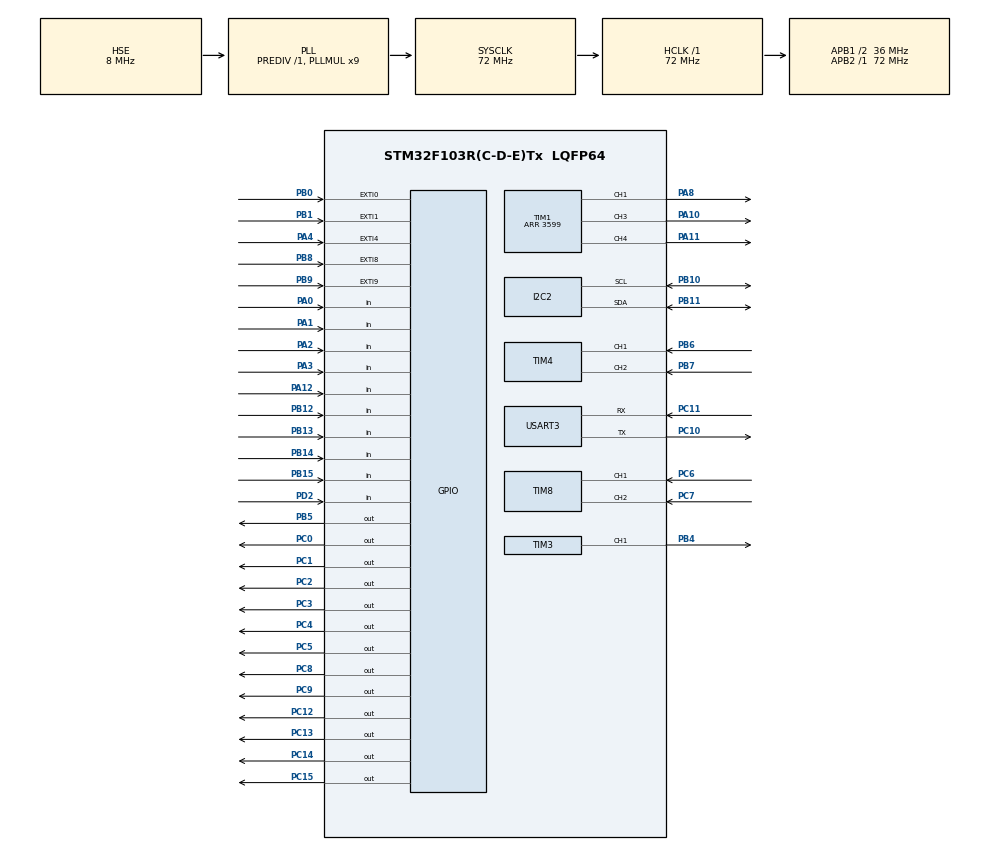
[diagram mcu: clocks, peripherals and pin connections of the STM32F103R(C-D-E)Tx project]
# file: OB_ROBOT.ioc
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Mcu.Family=STM32F1
Mcu.Name=STM32F103R(C-D-E)Tx
Mcu.Package=LQFP64
NVIC.EXTI0_IRQn=true\:0\:0\:false\:false\:true\:true\:true\:true
NVIC.EXTI1_IRQn=true\:0\:0\:false\:false\:true\:true\:true\:true
NVIC.EXTI4_IRQn=true\:0\:0\:false\:false\:true\:true\:true\:true
NVIC.EXTI9_5_IRQn=true\:0\:0\:false\:false\:true\:true\:true\:true
NVIC.PriorityGroup=NVIC_PRIORITYGROUP_4
NVIC.TIM2_IRQn=true\:1\:0\:false\:false\:true\:true\:true\:true
NVIC.USART3_IRQn=true\:0\:0\:false\:false\:true\:true\:true\:true
PA0-WKUP.GPIO_PuPd=GPIO_PULLDOWN
PA0-WKUP.Signal=GPIO_Input
PA1.GPIO_PuPd=GPIO_PULLUP
PA1.Signal=GPIO_Input
PA10.Signal=S_TIM1_CH3
PA11.Signal=S_TIM1_CH4
PA12.GPIO_PuPd=GPIO_PULLUP
PA12.Signal=GPIO_Input
PA13.Mode=Serial_Wire
PA13.Signal=SYS_JTMS-SWDIO
PA14.Mode=Serial_Wire
PA14.Signal=SYS_JTCK-SWCLK
PA2.GPIO_PuPd=GPIO_PULLUP
PA2.Signal=GPIO_Input
PA3.GPIO_PuPd=GPIO_PULLUP
PA3.Signal=GPIO_Input
PA4.GPIO_ModeDefaultEXTI=GPIO_MODE_IT_RISING
PA4.GPIO_PuPd=GPIO_NOPULL
PA4.Signal=GPXTI4
PA8.Signal=S_TIM1_CH1
PB0.GPIO_ModeDefaultEXTI=GPIO_MODE_IT_RISING_FALLING
PB0.GPIO_PuPd=GPIO_PULLUP
PB0.Signal=GPXTI0
PB1.GPIO_ModeDefaultEXTI=GPIO_MODE_IT_RISING_FALLING
PB1.GPIO_PuPd=GPIO_PULLUP
PB1.Signal=GPXTI1
PB10.Mode=I2C
PB10.Signal=I2C2_SCL
PB11.Mode=I2C
PB11.Signal=I2C2_SDA
PB12.GPIO_PuPd=GPIO_PULLUP
PB12.Signal=GPIO_Input
PB13.GPIO_PuPd=GPIO_PULLUP
PB13.Signal=GPIO_Input
PB14.GPIO_PuPd=GPIO_PULLUP
PB14.Signal=GPIO_Input
PB15.GPIO_PuPd=GPIO_PULLUP
PB15.Signal=GPIO_Input
PB4.Signal=S_TIM3_CH1
PB5.GPIO_Speed=GPIO_SPEED_FREQ_HIGH
PB5.Signal=GPIO_Output
PB6.Signal=S_TIM4_CH1
PB7.Signal=S_TIM4_CH2
PB8.GPIO_ModeDefaultEXTI=GPIO_MODE_IT_RISING_FALLING
PB8.GPIO_PuPd=GPIO_PULLUP
PB8.Signal=GPXTI8
PB9.GPIO_ModeDefaultEXTI=GPIO_MODE_IT_RISING_FALLING
PB9.GPIO_PuPd=GPIO_PULLUP
PB9.Signal=GPXTI9
PC0.GPIO_Speed=GPIO_SPEED_FREQ_HIGH
PC0.Signal=GPIO_Output
PC1.GPIO_Speed=GPIO_SPEED_FREQ_HIGH
PC1.Signal=GPIO_Output
PC10.Mode=Asynchronous
PC10.Signal=USART3_TX
PC11.Mode=Asynchronous
PC11.Signal=USART3_RX
PC12.GPIO_ModeDefaultOutputPP=GPIO_MODE_OUTPUT_PP
PC12.GPIO_Speed=GPIO_SPEED_FREQ_HIGH
PC12.Signal=GPIO_Output
PC13-TAMPER-RTC.GPIO_PuPd=GPIO_PULLUP
PC13-TAMPER-RTC.Signal=GPIO_Output
PC14-OSC32_IN.GPIO_PuPd=GPIO_PULLUP
PC14-OSC32_IN.Signal=GPIO_Output
PC15-OSC32_OUT.GPIO_PuPd=GPIO_PULLUP
PC15-OSC32_OUT.Signal=GPIO_Output
PC2.GPIO_Speed=GPIO_SPEED_FREQ_HIGH
PC2.Signal=GPIO_Output
PC3.GPIO_Speed=GPIO_SPEED_FREQ_HIGH
PC3.Signal=GPIO_Output
PC4.GPIO_Speed=GPIO_SPEED_FREQ_HIGH
PC4.Signal=GPIO_Output
PC5.GPIO_Speed=GPIO_SPEED_FREQ_HIGH
PC5.Signal=GPIO_Output
PC6.Signal=S_TIM8_CH1
PC7.Signal=S_TIM8_CH2
PC8.GPIO_Speed=GPIO_SPEED_FREQ_HIGH
PC8.Signal=GPIO_Output
PC9.GPIO_Speed=GPIO_SPEED_FREQ_HIGH
PC9.Signal=GPIO_Output
PD0-OSC_IN.Mode=HSE-External-Oscillator
PD0-OSC_IN.Signal=RCC_OSC_IN
PD1-OSC_OUT.Mode=HSE-External-Oscillator
PD1-OSC_OUT.Signal=RCC_OSC_OUT
PD2.GPIO_PuPd=GPIO_PULLUP
PD2.Signal=GPIO_Input
ProjectManager.HeapSize=0x200
ProjectManager.StackSize=0x400
ProjectManager.TargetToolchain=MDK-ARM V5
RCC.AHBFreq_Value=72000000
RCC.APB1CLKDivider=RCC_HCLK_DIV2
RCC.APB1Freq_Value=36000000
RCC.APB1TimFreq_Value=72000000
RCC.APB2Freq_Value=72000000
RCC.APB2TimFreq_Value=72000000
RCC.HCLKFreq_Value=72000000
RCC.PLLMUL=RCC_PLL_MUL9
RCC.PLLSourceVirtual=RCC_PLLSOURCE_HSE
RCC.SYSCLKFreq_VALUE=72000000
RCC.SYSCLKSource=RCC_SYSCLKSOURCE_PLLCLK
RCC.USBFreq_Value=72000000
SH.S_TIM1_CH1.0=TIM1_CH1,PWM Generation1 CH1
SH.S_TIM1_CH3.0=TIM1_CH3,PWM Generation3 CH3
SH.S_TIM1_CH4.0=TIM1_CH4,PWM Generation4 CH4
SH.S_TIM3_CH1.0=TIM3_CH1,PWM Generation1 CH1
SH.S_TIM4_CH1.0=TIM4_CH1,Encoder_Interface
SH.S_TIM4_CH2.0=TIM4_CH2,Encoder_Interface
SH.S_TIM8_CH1.0=TIM8_CH1,Encoder_Interface
SH.S_TIM8_CH2.0=TIM8_CH2,Encoder_Interface
TIM1.Channel-PWM\ Generation1\ CH1=TIM_CHANNEL_1
TIM1.Channel-PWM\ Generation3\ CH3=TIM_CHANNEL_3
TIM1.Channel-PWM\ Generation4\ CH4=TIM_CHANNEL_4
TIM1.Period=3599
TIM2.Period=9999
TIM2.Prescaler=71
TIM3.Channel-PWM\ Generation1\ CH1=TIM_CHANNEL_1
TIM3.Period=3599
TIM4.AutoReloadPreload=TIM_AUTORELOAD_PRELOAD_ENABLE
TIM4.EncoderMode=TIM_ENCODERMODE_TI12
TIM8.AutoReloadPreload=TIM_AUTORELOAD_PRELOAD_ENABLE
TIM8.EncoderMode=TIM_ENCODERMODE_TI12
USART3.VirtualMode=VM_ASYNC
VP_TIM1_VS_ClockSourceINT.Mode=Internal
VP_TIM2_VS_ClockSourceINT.Mode=Internal
VP_TIM3_VS_ClockSourceINT.Mode=Internal
board=custom

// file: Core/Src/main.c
/* USER CODE BEGIN Header */
/* USER CODE END Header */
#include "main.h"
#include "i2c.h"
#include "tim.h"
#include "usart.h"
#include "gpio.h"

/* USER CODE BEGIN Includes */
#include "app.h"
/* USER CODE END Includes */

void SystemClock_Config(void);

int main(void)
{
  HAL_Init();
  SystemClock_Config();

  MX_GPIO_Init();
  MX_TIM1_Init();
  MX_TIM3_Init();
  MX_TIM4_Init();
  MX_TIM8_Init();
  MX_USART3_UART_Init();
  MX_TIM2_Init();
  MX_I2C2_Init();

  /* USER CODE BEGIN 2 */
  App_Init();
  /* USER CODE END 2 */

  /* Infinite loop */
  /* USER CODE BEGIN WHILE */
  while (1)
  {
    App_Run();
    /* USER CODE END WHILE */

  }
}

void SystemClock_Config(void)
{
  RCC_OscInitTypeDef RCC_OscInitStruct = {0};
  RCC_ClkInitTypeDef RCC_ClkInitStruct = {0};

  RCC_OscInitStruct.OscillatorType = RCC_OSCILLATORTYPE_HSE;
  RCC_OscInitStruct.HSEState = RCC_HSE_ON;
  RCC_OscInitStruct.HSEPredivValue = RCC_HSE_PREDIV_DIV1;
  RCC_OscInitStruct.HSIState = RCC_HSI_ON;
  RCC_OscInitStruct.PLL.PLLState = RCC_PLL_ON;
  RCC_OscInitStruct.PLL.PLLSource = RCC_PLLSOURCE_HSE;
  RCC_OscInitStruct.PLL.PLLMUL = RCC_PLL_MUL9;
  if (HAL_RCC_OscConfig(&RCC_OscInitStruct) != HAL_OK)
  {
    Error_Handler();
  }

  RCC_ClkInitStruct.ClockType = RCC_CLOCKTYPE_HCLK|RCC_CLOCKTYPE_SYSCLK
                              |RCC_CLOCKTYPE_PCLK1|RCC_CLOCKTYPE_PCLK2;
  RCC_ClkInitStruct.SYSCLKSource = RCC_SYSCLKSOURCE_PLLCLK;
  RCC_ClkInitStruct.AHBCLKDivider = RCC_SYSCLK_DIV1;
  RCC_ClkInitStruct.APB1CLKDivider = RCC_HCLK_DIV2;
  RCC_ClkInitStruct.APB2CLKDivider = RCC_HCLK_DIV1;

  if (HAL_RCC_ClockConfig(&RCC_ClkInitStruct, FLASH_LATENCY_2) != HAL_OK)
  {
    Error_Handler();
  }
}

void Error_Handler(void)
{
  __disable_irq();
  while (1)
  {
  }
}

#ifdef USE_FULL_ASSERT
void assert_failed(uint8_t *file, uint32_t line)
{
  /* USER CODE BEGIN 6 */
  (void)file;
  (void)line;
  /* USER CODE END 6 */
}
#endif /* USE_FULL_ASSERT */
